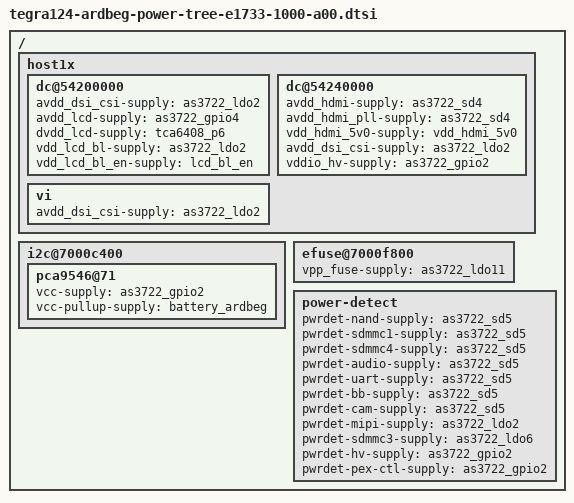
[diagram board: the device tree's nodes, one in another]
#include "tegra124-platforms/tegra124-ardbeg-pmic-e1733-1000-a00.dtsi"
#include "tegra124-platforms/tegra124-ardbeg-fixed-e1733-1000-a00.dtsi"

/ {
	host1x {
		/* tegradc.0 */
		dc@54200000 {
			avdd_dsi_csi-supply = <&as3722_ldo2>;
			avdd_lcd-supply = <&as3722_gpio4>;
			dvdd_lcd-supply = <&tca6408_p6>;
			vdd_lcd_bl-supply = <&as3722_ldo2>;
			vdd_lcd_bl_en-supply = <&lcd_bl_en>;
		};

		/* tegradc.1 */
		dc@54240000 {
			avdd_hdmi-supply = <&as3722_sd4>;
			avdd_hdmi_pll-supply = <&as3722_sd4>;
			vdd_hdmi_5v0-supply = <&vdd_hdmi_5v0>;
			avdd_dsi_csi-supply = <&as3722_ldo2>;
			vddio_hv-supply = <&as3722_gpio2>;
		};
		vi {
			avdd_dsi_csi-supply = <&as3722_ldo2>;
		};
	};

	i2c@7000c400 {
		pca9546@71 {
			vcc-supply = <&as3722_gpio2>;
			vcc-pullup-supply = <&battery_ardbeg>;
		};
	};

	efuse@7000f800 {
		vpp_fuse-supply = <&as3722_ldo11>;
	};

	power-detect {
		pwrdet-nand-supply = <&as3722_sd5>;
		pwrdet-sdmmc1-supply = <&as3722_sd5>;
		pwrdet-sdmmc4-supply = <&as3722_sd5>;
		pwrdet-audio-supply = <&as3722_sd5>;
		pwrdet-uart-supply = <&as3722_sd5>;
		pwrdet-bb-supply = <&as3722_sd5>;
		pwrdet-cam-supply = <&as3722_sd5>;
		pwrdet-mipi-supply = <&as3722_ldo2>;
		pwrdet-sdmmc3-supply = <&as3722_ldo6>;
		pwrdet-hv-supply = <&as3722_gpio2>;
		pwrdet-pex-ctl-supply = <&as3722_gpio2>;
	}; 
};
